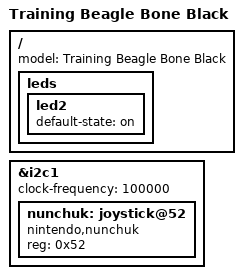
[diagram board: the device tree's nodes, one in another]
// SPDX-License-Identifier: GPL-2.0-only
/*
 * Copyright (C) 2015-2020 Bootlin - https://bootlin.com/
 *
 * Also available on
 * SOLUTION_URL
 *
 * This program is free software; you can redistribute it and/or modify
 * it under the terms of the GNU General Public License version 2 as
 * published by the Free Software Foundation.
 */
/dts-v1/;

/* For BeableBone Black, use instead:
 * #include "am335x-boneblack.dts"
 */
#include "am335x-boneblack-wireless.dts"

/ {
       model = "Training Beagle Bone Black";
       leds{
              led2 {
                     default-state = "on";
              };
       };
};


&i2c1 {
	status = "okay";
	clock-frequency = <100000>;

	nunchuk: joystick@52 {
		compatible = "nintendo,nunchuk";
		reg = <0x52>;
	};
};
